AUTOSAR XML (schema 4-0-3)
package /ComponentTypes
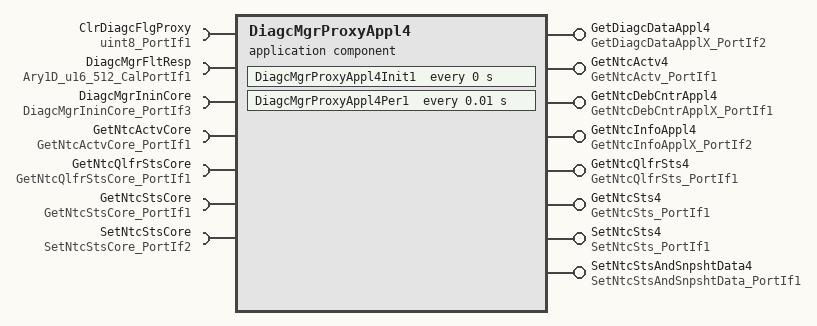
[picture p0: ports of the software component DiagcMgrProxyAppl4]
  application sw component type DiagcMgrProxyAppl4
    8 x provide port, all with server-com-spec{operation=Oper, queue-length=1}:
      GetDiagcDataAppl4: provided-interface=GetDiagcDataApplX_PortIf2
      GetNtcActv4: provided-interface=GetNtcActv_PortIf1
      GetNtcDebCntrAppl4: provided-interface=GetNtcDebCntrApplX_PortIf1
      GetNtcInfoAppl4: provided-interface=GetNtcInfoApplX_PortIf2
      GetNtcQlfrSts4: provided-interface=GetNtcQlfrSts_PortIf1
      GetNtcSts4: provided-interface=GetNtcSts_PortIf1
      SetNtcSts4: provided-interface=SetNtcSts_PortIf1
      SetNtcStsAndSnpshtData4: provided-interface=SetNtcStsAndSnpshtData_PortIf1
    7 x require port:
      ClrDiagcFlgProxy: nonqueued-receiver-com-spec{data-element=Val, filter=data-filter-type=ALWAYS, init-value=0}, required-interface=uint8_PortIf1
      DiagcMgrFltResp: parameter-require-com-spec{init-value=[0, 34560, 34560, 34560, 34560, 34560, 34560, 34560, 34560, 34560, 34560, 34560, 34560, 34560, 34560, 34560, 34560, 34560, 34560, 34560, 34560, 34560, 34560, 34560, 34560, 34560, 34560, 34560, 34560, 34560, 34560, 34560, 34560, 34560, 34560, 34560, 34560, 34560, 34560, 34560, 34560, 34560, 34560, 34560, 34560, 34560, 34560, 34560, 34560, 34560, 34560, 34560, 34560, 34560, 34560, 34560, 34560, 34560, 34560, 34560, 34560, 34560, 34560, 34560, 34560, 34560, 34560, 34560, 34560, 34560, 34560, 34560, 34560, 34560, 34560, 34560, 34560, 34560, 34560, 34560, 34560, 34560, 34560, 34560, 34560, 34560, 34560, 34560, 34560, 34560, 34560, 34560, 34560, 34560, 34560, 34560, 34560, 34560, 34560, 34560, 34560, 34560, 34560, 34560, 34560, 34560, 34560, 34560, 34560, 34560, 34560, 34560, 34560, 34560, 34560, 34560, 34560, 34560, 34560, 34560, 34560, 34560, 34560, 34560, 34560, 34560, 34560, 34560, 34560, 34560, 34560, 34560, 34560, 34560, 34560, 34560, 34560, 34560, 34560, 34560, 34560, 34560, 34560, 34560, 34560, 34560, 34560, 34560, 34560, 34560, 34560, 34560, 34560, 34560, 34560, 34560, 34560, 34560, 34560, 34560, 34560, 34560, 34560, 34560, 34560, 34560, 34560, 34560, 34560, 34560, 34560, 34560, 34560, 34560, 34560, 34560, 34560, 34560, 34560, 34560, 34560, 34560, 34560, 34560, 34560, 34560, 34560, 34560, 34560, 34560, 34560, 34560, 34560, 34560, 34560, 34560, 34560, 34560, 34560, 34560, 34560, 34560, 34560, 34560, 34560, 34560, 34560, 34560, 34560, 34560, 34560, 34560, 34560, 34560, 34560, 34560, 34560, 34560, 34560, 34560, 34560, 34560, 34560, 34560, 34560, 34560, 34560, 34560, 34560, 34560, 34560, 34560, 34560, 34560, 34560, 34560, 34560, 34560, 34560, 34560, 34560, 34560, 34560, 34560, 34560, 34560, 34560, 34560, 34560, 34560, 34560, 34560, 34560, 34560, 34560, 34560, 34560, 34560, 34560, 34560, 34560, 34560, 34560, 34560, 34560, 34560, 34560, 34560, 34560, 34560, 34560, 34560, 34560, 34560, 34560, 34560, 34560, 34560, 34560, 34560, 34560, 34560, 34560, 34560, 34560, 34560, 34560, 34560, 34560, 34560, 34560, 34560, 34560, 34560, 34560, 34560, 34560, 34560, 34560, 34560, 34560, 34560, 34560, 34560, 34560, 34560, 34560, 34560, 34560, 34560, 34560, 34560, 34560, 34560, 34560, 34560, 34560, 34560, 34560, 34560, 34560, 34560, 34560, 34560, 34560, 34560, 34560, 34560, 34560, 34560, 34560, 34560, 34560, 34560, 34560, 34560, 34560, 34560, 34560, 34560, 34560, 34560, 34560, 34560, 34560, 34560, 34560, 34560, 34560, 34560, 34560, 34560, 34560, 34560, 34560, 34560, 34560, 34560, 34560, 34560, 34560, 34560, 34560, 34560, 34560, 34560, 34560, 34560, 34560, 34560, 34560, 34560, 34560, 34560, 34560, 34560, 34560, 34560, 34560, 34560, 34560, 34560, 34560, 34560, 34560, 34560, 34560, 34560, 34560, 34560, 34560, 34560, 34560, 34560, 34560, 34560, 34560, 34560, 34560, 34560, 34560, 34560, 34560, 34560, 34560, 34560, 34560, 34560, 34560, 34560, 34560, 34560, 34560, 34560, 34560, 34560, 34560, 34560, 34560, 34560, 34560, 34560, 34560, 34560, 34560, 34560, 34560, 34560, 34560, 34560, 34560, 34560, 34560, 34560, 34560, 34560, 34560, 34560, 34560, 34560, 34560, 34560, 34560, 34560, 34560, 34560, 34560, 34560, 34560, 34560, 34560, 34560, 34560, 34560, 34560, 34560, 34560, 34560, 34560, 34560, 34560, 34560, 34560, 34560, 34560, 34560, 34560, 34560, 34560, 34560, 34560, 34560, 34560, 34560, 34560, 34560, 34560, 34560, 34560, 34560, 34560, 34560, 34560, 34560, 34560, 34560, 34560, 34560, 34560, 34560, 34560, 34560, 34560, 34560, 34560, 34560, 34560, 34560, 34560, 34560, 34560, 34560, 34560, 34560, 34560, 34560, 34560, 34560, 34560, 34560, 34560, 34560], parameter=Ary1D}, required-interface=Ary1D_u16_512_CalPortIf1
      DiagcMgrIninCore: client-com-spec=Oper, required-interface=DiagcMgrIninCore_PortIf3
      GetNtcActvCore: client-com-spec=Oper, required-interface=GetNtcActvCore_PortIf1
      GetNtcQlfrStsCore: client-com-spec=Oper, required-interface=GetNtcQlfrStsCore_PortIf1
      GetNtcStsCore: client-com-spec=Oper, required-interface=GetNtcStsCore_PortIf1
      SetNtcStsCore: client-com-spec=Oper, required-interface=SetNtcStsCore_PortIf2
    behavior DiagcMgrProxyAppl4_InternalBehavior
      exclusive area DiagcMgrProxyAppl4
      ar-typed-per-instance-memorys:
        5 x data:
          DiagcData4: sw-calibration-access=READ-ONLY, type=DiagcDataRec2
          DiagcMgrNtcInfo4Ary: type=Ary1D_NtcInfoRec4_DiagcMgrProxyAppl4
          DiagcMgrNtcInfo4DebCntrAry: type=Ary1D_s16_DiagcMgrProxyAppl4
          PrevClrNtcFlg4: sw-calibration-access=READ-ONLY, type=uint8
          ProxySetNtcData4: sw-calibration-access=READ-ONLY, type=DiagcDataRec2
      timing event DiagcMgrProxyAppl4_InitEvent: start-on-event=DiagcMgrProxyAppl4Init1, period=0
      timing event TMT_DiagcMgrProxyAppl4Per1: start-on-event=DiagcMgrProxyAppl4Per1, period=0.01
      8 x operation invoked event:
        OIT_GetDiagcDataAppl4_Oper_GetDiagcDataAppl4_Oper: start-on-event=GetDiagcDataAppl4_Oper, operation=GetDiagcDataAppl4.Oper
        OIT_GetNtcActv4_Oper_GetNtcActv4_Oper: start-on-event=GetNtcActv4_Oper, operation=GetNtcActv4.Oper
        OIT_GetNtcDebCntrAppl4_Oper_GetNtcDebCntrAppl4_Oper: start-on-event=GetNtcDebCntrAppl4_Oper, operation=GetNtcDebCntrAppl4.Oper
        OIT_GetNtcInfoAppl4_Oper_GetNtcInfoAppl4_Oper: start-on-event=GetNtcInfoAppl4_Oper, operation=GetNtcInfoAppl4.Oper
        OIT_GetNtcQlfrSts4_Oper_GetNtcQlfrSts4_Oper: start-on-event=GetNtcQlfrSts4_Oper, operation=GetNtcQlfrSts4.Oper
        OIT_GetNtcSts4_Oper_GetNtcSts4_Oper: start-on-event=GetNtcSts4_Oper, operation=GetNtcSts4.Oper
        OIT_SetNtcSts4_Oper_SetNtcSts4_Oper: start-on-event=SetNtcSts4_Oper, operation=SetNtcSts4.Oper
        OIT_SetNtcStsAndSnpshtData4_Oper_SetNtcStsAndSnpshtData4_Oper: start-on-event=SetNtcStsAndSnpshtData4_Oper, operation=SetNtcStsAndSnpshtData4.Oper
      10 x runnable:
        DiagcMgrProxyAppl4Init1
          sync call SC_DiagcMgrIninCore_Oper: operation=DiagcMgrIninCore.Oper, timeout=0
        DiagcMgrProxyAppl4Per1: can-enter-exclusive-area=DiagcMgrProxyAppl4
          data-receive-point-by-arguments:
            access REC_ClrNtcFlg_Val: accessed-variable=ClrDiagcFlgProxy.Val
        GetDiagcDataAppl4_Oper
        GetNtcActv4_Oper: can-be-invoked-concurrently=true
          sync call SC_GetNtcActvCore_Oper: operation=GetNtcActvCore.Oper, timeout=0
        GetNtcDebCntrAppl4_Oper: can-be-invoked-concurrently=true
        GetNtcInfoAppl4_Oper: can-be-invoked-concurrently=true
        GetNtcQlfrSts4_Oper: can-be-invoked-concurrently=true
          sync call SC_GetNtcQlfrStsCore_Oper: operation=GetNtcQlfrStsCore.Oper, timeout=0
        GetNtcSts4_Oper: can-be-invoked-concurrently=true
          sync call SC_GetNtcStsCore_Oper: operation=GetNtcStsCore.Oper, timeout=0
        SetNtcSts4_Oper: can-be-invoked-concurrently=true
          sync call SC_SetNtcStsCore_Oper: operation=SetNtcStsCore.Oper, timeout=0
        SetNtcStsAndSnpshtData4_Oper: can-be-invoked-concurrently=true
          sync call SC_SetNtcStsCore_Oper: operation=SetNtcStsCore.Oper, timeout=0
  swc implementation DiagcMgrProxyAppl4_Implementation: behavior=DiagcMgrProxyAppl4_InternalBehavior
    code-descriptors:
      code Default: artifact-descriptors=autosar-engineering-object={short-label=Default, category=SWSRC}
